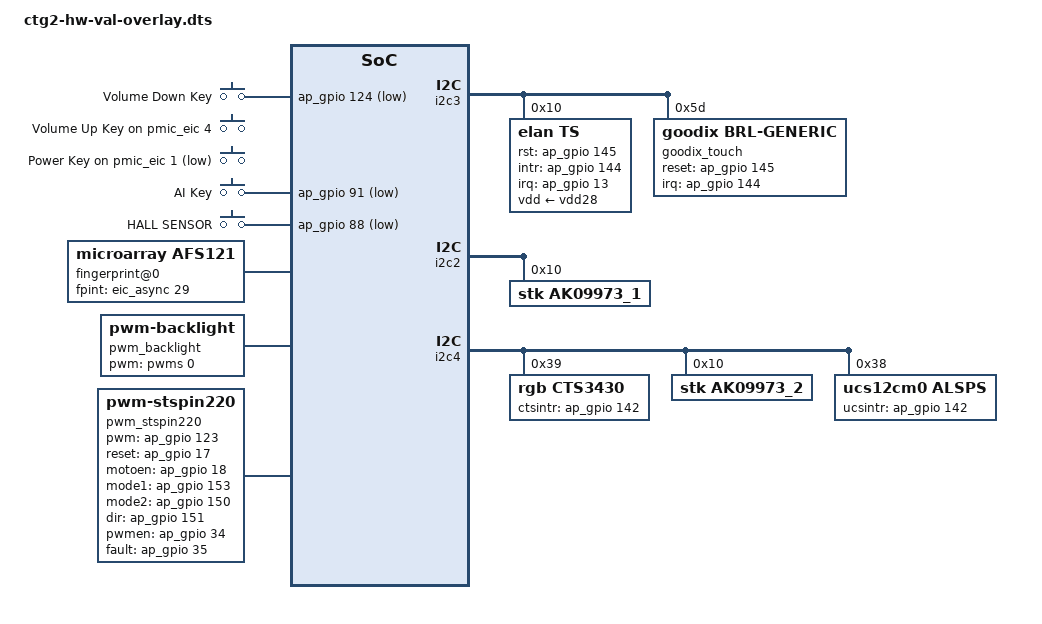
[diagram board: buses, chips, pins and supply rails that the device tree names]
// Device tree overlay for CTG2 devices
//
// Copyright (C) 2021, Anhui Yunshu Zhihui Technology Co., Ltd.
//
// SPDX-License-Identifier: GPL-2.0-only

/dts-v1/;
/plugin/;

#include <dt-bindings/input/input.h>
#include <dt-bindings/gpio/gpio.h>

/ {
	fragment {
		target-path = "/";
		__overlay__ {

			gpio-keys {
				compatible = "gpio-keys";

				key-volumedown {
					label = "Volume Down Key";
					linux,code = <KEY_VOLUMEDOWN>;
					gpios = <&ap_gpio 124 GPIO_ACTIVE_LOW>;
					debounce-interval = <2>;
					wakeup-source;
				};

				key-volumeup {
					label = "Volume Up Key";
					linux,code = <KEY_VOLUMEUP>;
					gpios = <&pmic_eic 4 GPIO_ACTIVE_HIGH>;
					debounce-interval = <2>;
					wakeup-source;
				};

				key-power {
					label = "Power Key";
					linux,code = <KEY_POWER>;
					gpios = <&pmic_eic 1 GPIO_ACTIVE_LOW>;
					debounce-interval = <2>;
					wakeup-source;
				};

				key-ai {
					label = "AI Key";
					linux,code = <KEY_F5>;
					gpios = <&ap_gpio 91 GPIO_ACTIVE_LOW>;
					debounce-interval = <2>;
					wakeup-source;
				};

				key-hallsensor {
					label = "HALL SENSOR";
					linux,code = <KEY_RESERVED>;
					linux,input-type = <5>;
					gpios = <&ap_gpio 88 GPIO_ACTIVE_LOW>;
					debounce-interval = <2>;
					wakeup-source;
				};
			};

			fingerprint@0 {
				compatible = "microarray,afs121";
				fpint-gpios = <&eic_async 29 0>;
			};

			pwm_backlight: sprd_backlight {
				compatible = "pwm-backlight";
				pwms = <&pwms 0 666667>;
				pwm-names = "backlight";
				brightness-levels = <
                    2   2   2   2   2   2   2   2
                    2   2   2   3   4   5   6   7   8   9
                    10  11  12  13  14  15  16  17  18  19
                    20  21  22  23  24  25  26  27  28  29
                    30  31  32  33  34  35  36  37  38  39
                    40  41  42  43  44  45  46  47  48  49
                    50  51  52  53  54  55  56  57  58  59
                    60  61  62  63  64  65  66  67  68  69
                    70  71  72  73  74  75  76  77  78  79
                    80  81  82  83  84  85  86  87  88  89
                    90  91  92  93  94  95  96  97  98  99
                    100 101 102 103 104 105 106 107 108 109
                    110 111 112 113 114 115 116 117 118 119
                    120 121 122 123 124 125 126 127 128 129
                    130 131 132 133 134 135 136 137 138 139
                    140 141 142 143 144 145 146 147 148 149
                    150 151 152 153 154 155 156 157 158 159
                    160 161 162 163 164 165 166 167 168 169
                    170 171 172 173 174 175 176 177 178 179
                    180 181 182 183 184 185 186 187 188 189
                    190 191 192 193 194 195 196 197 198 199
                    200 201 202 203 204 205 206 207 208 209
                    210 211 212 213 214 215 216 217 218 219
                    220 221 222 223 224 225 226 227 228 229
                    230 231 232 233 234 235 236 237 238 239
                    240 241 242 243 244 245 246 247 248 249
                    250 251 252 253 254 255 256 257 258 259
                    260 261 262 263 264 265 266 267 268 269
                    270 271 272 273 274 275 276 277 278 279
                    280 281 282 283 284 285 286 287 288 289
                    290 291 292 293 294 295 296 297 298 299
                    300 301 302 303 304 305 306 307 308 309
                    310 311 312 313 314 315 316 317 318 319
                    320 321 322 323 324 325 326 327 328 329
                    330 331 332 333 334 335 336 337 338 339
                    340 341 342 343 344 345 346 347 348 349
                    350 351 352 353 354 355 356 357 358 359
                    360 361 362 363 364 365 366 367 368 369
                    370 371 372 373 374 375 376 377 378 379
                    380 381 382 383 384 385 386 387 388 389
                    390 391 392 393 394 395 396 397 398 399
                    400 401 402 403 404 405 406 407 408 409
                    410 411 412 413 414 415 416 417 418 419
                    420 421 422 423 424 425 426 427 428 429
                    430 431 432 433 434 435 436 437 438 439
                    440 441 442 443 444 445 446 447 448 449
                    450 451 452 453 454 455 456 457 458 459
                    460 461 462 463 464 465 466 467 468 469
                    470 471 472 473 474 475 476 477 478 479
                    480 481 482 483 484 485 486 487 488 489
                    490 491 492 493 494 495 496 497 498 499
                    500 501 502 503 504 505 506 507 508 509
                    510 511 512 513 514 515 516 517 518 519
                    520 521 522 523 524 525 526 527 528 529
                    530 531 532 533 534 535 536 537 538 539
                    540 541 542 543 544 545 546 547 548 549
                    550 551 552 553 554 555 556 557 558 559
                    560 561 562 563 564 565 566 567 568 569
                    570 571 572 573 574 575 576 577 578 579
                    580 581 582 583 584 585 586 587 588 589
                    590 591 592 593 594 595 596 597 598 599
                    600 601 602 603 604 605 606 607 608 609
                    610 611 612 613 614 615 616 617 618 619
                    620 621 622 623 624 625 626 627 628 629
                    630 631 632 633 634 635 636 637 638 639
                    640 641 642 643 644 645 646 647 648 649
                    650 651 652 653 654 655 656 657 658 659
                    660 661 662 663 664 665 666 667 668 669
                    670 671 672 673 674 675 676 677 678 679
                    680 681 682 683 684 685 686 687 688 689
                    690 691 692 693 694 695 696 697 698 699
                    700 701 702 703 704 705 706 707 708 709
                    710 711 712 713 714 715 716 717 718 719
                    720 721 722 723 724 725 726 727 728 729
                    730 731 732 733 734 735 736 737 738 739
                    740 741 742 743 744 745 746 747 748 749
                    750 751 752 753 754 755 756 757 758 759
                    760 761 762 763 764 765 766 767 768 769
                    770 771 772 773 774 775 776 777 778 779
                    780 781 782 783 784 785 786 787 788 789
                    790 791 792 793 794 795 796 797 798 799
                    800 801 802 803 804 805 806 807 808 809
                    810 811 812 813 814 815 816 817 818 819
                    820 821 822 823 824 825 826 827 828 829
                    830 831 832 833 834 835 836 837 838 839
                    840 841 842 843 844 845 846 847 848 849
                    850 851 852 853 854 855 856 857 858 859
                    860 861 862 863 864 865 866 867 868 869
                    870 861 872 873 874 875 876 877 878 879
                    880 881 882 883 884 885 886 887 888 889
                    890 891 892 893 894 895 896 897 898 899
                    900 901 902 903 904 905 906 907 908 909
                    910 911 912 913 914 915 916 917 918 919
                    920 921 922 923 924 925 926 927 928 929
                    930 931 932 933 934 935 936 937 938 939
                    940 941 942 943 944 945 946 947 948 949
                    950 951 952 953 954 955 956 957 958 959
                    960 961 962 963 964 965 966 967 968 969
                    970 961 972 973 974 975 976 977 978 979
                    980 981 982 983 984 985 986 987 988 989
                    990 991 992 993 994 995 996 997 998 999
                    1000 1001 1002 1003 1004 1005 1006 1007
                    1008 1009 1010 1011 1012 1013 1014 1015
                    1016 1017 1018 1019 1020 1021 1023
					>;
				default-brightness-level = <408>;
			};
			pwm_stspin220: pwm_stspin220 {
				compatible = "pwm-stspin220";
				pwms = <&pwms 1 80000>;
				pwm-names = "stspin220";
				//vdd_vib-supply = <&vddvibr>;
				vddsdio-supply = <&vddsdio>;
				pwm-gpios = <&ap_gpio 123 GPIO_ACTIVE_HIGH>;
				reset-gpios = <&ap_gpio 17 GPIO_ACTIVE_HIGH>;
				motoen-gpios = <&ap_gpio 18 GPIO_ACTIVE_HIGH>;
				mode1-gpios = <&ap_gpio 153 GPIO_ACTIVE_HIGH>;
				mode2-gpios = <&ap_gpio 150 GPIO_ACTIVE_HIGH>;
				dir-gpios = <&ap_gpio 151 GPIO_ACTIVE_HIGH>;
				pwmen-gpios = <&ap_gpio 34 GPIO_ACTIVE_HIGH>;
				fault-gpios = <&ap_gpio 35 GPIO_ACTIVE_HIGH>;
			};
		};
     };
};

&i2c3 {
	status = "okay";

/*
	synaptics-touch@20 {
		compatible = "synaptics,dsx";
		reg = <0x20>;
		gpios = <&ap_gpio 145 GPIO_ACTIVE_HIGH
			&ap_gpio 144 GPIO_ACTIVE_HIGH>;
	};

	touchscreen@53 {
		compatible = "solomon,ssd20xx";
		reg = <0x53>;
		gpios = <&ap_gpio 145 GPIO_ACTIVE_HIGH
			&ap_gpio 144 GPIO_ACTIVE_HIGH>;
	};
*/
    elan@10 {
        compatible = "elan,ts";
        reg = <0x10>;
        interrupt-parent = <&ap_gpio>;
        interrupts = <13 0x02>;
        elan,rst-gpio = <&ap_gpio 145 GPIO_ACTIVE_HIGH>;
        elan,intr-gpio = <&ap_gpio 144 GPIO_ACTIVE_HIGH>;
        vdd-supply = <&vdd28>;
        //vdd_i2c-supply = <&vdd28>;
    };

    goodix_touch@5d {
	compatible = "goodix,brl-generic";
	reg = <0x5d>;
	goodix,reset-gpio = <&ap_gpio 145 GPIO_ACTIVE_HIGH>;
	goodix,irq-gpio = <&ap_gpio 144 GPIO_ACTIVE_HIGH>;
	goodix,irq-flags = <2>;
	goodix,panel-max-id = <10>;
	goodix,panel-max-x = <1350>;
	goodix,panel-max-y = <2160>;
	goodix,panel-max-w = <512>;
	goodix,panel-max-p = <4096>;
	goodix,panel-on-delay-us = <300000>;
	goodix,panel-off-delay-us = <5000>;
	goodix,pen-enable;
	goodix,key-of-pen = <331 332>;
	sensor0{
		normal-cfg = [];
	};
    };
};

&panel {
	sprd,backlight = <&pwm_backlight>;
};

&ddr_dfs {
	sprd-scene = "boost", "lcdon", "lcdoff", "camlow",
		"camhigh", "camveryhigh";
	sprd-freq = <1333 768 256 384 667 1333>;
};


&i2c2 {
	status = "okay";
	ak09973_1@10 {
		compatible = "stk,ak09973_1";
		reg = <0x10>;
	};

};
&i2c4 {
	status = "okay";
	cts3430@39 {
		compatible = "rgb,cts3430";
		reg = <0x39>;
        interrupt-parent = <&ap_gpio>;
		ctsintr-gpio = <&ap_gpio 142 GPIO_ACTIVE_HIGH>;
	};

	ak09973_2@10 {
		compatible = "stk,ak09973_2";
		reg = <0x10>;
	};
    ucs12cm0@38 {
       compatible = "ucs12cm0,alsps";
       reg = <0x38>;
       interrupt-parent = <&ap_gpio>;
       ucsintr-gpio = <&ap_gpio 142 GPIO_ACTIVE_HIGH>;
    };


};

&vddemmccore {
	regulator-always-on;
};

